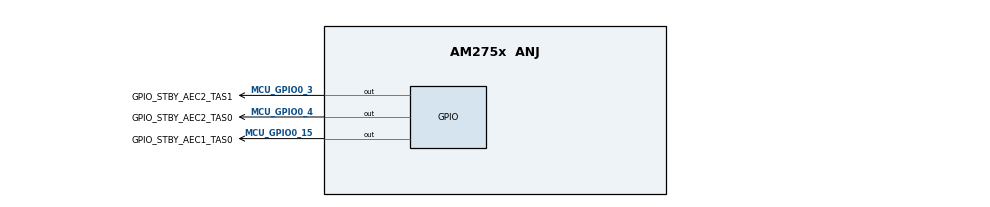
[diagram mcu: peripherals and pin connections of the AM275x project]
/**
 * @cliArgs --device "AM275x" --part "AM2754" --package "ANJ" --context "c75ss0-0" --product "MCU_PLUS_SDK@07.03.01"
 * @versions {"tool":"1.24.0+4150"}
 */

/**
 * Import the modules used in this configuration.
 */
const gpio        = scripting.addModule("/drivers/gpio/gpio", {}, false);
const gpio1       = gpio.addInstance();
const gpio2       = gpio.addInstance();
const gpio3       = gpio.addInstance();
const gpio4       = gpio.addInstance();
const i2c         = scripting.addModule("/drivers/i2c/i2c", {}, false);
const i2c1        = i2c.addInstance();
const i2c2        = i2c.addInstance();
const mcasp       = scripting.addModule("/drivers/mcasp/mcasp", {}, false);
const mcasp1      = mcasp.addInstance();
const mcasp2      = mcasp.addInstance();
const debug_log   = scripting.addModule("/kernel/dpl/debug_log");
const mmu_armv8   = scripting.addModule("/kernel/dpl/mmu_armv8", {}, false);
const mmu_armv81  = mmu_armv8.addInstance();
const mmu_armv82  = mmu_armv8.addInstance();
const mmu_armv83  = mmu_armv8.addInstance();
const mmu_armv84  = mmu_armv8.addInstance();
const mmu_armv85  = mmu_armv8.addInstance();
const mmu_armv86  = mmu_armv8.addInstance();
const mmu_armv87  = mmu_armv8.addInstance();
const mmu_armv88  = mmu_armv8.addInstance();
const mmu_armv89  = mmu_armv8.addInstance();
const mmu_armv810 = mmu_armv8.addInstance();
const mmu_armv811 = mmu_armv8.addInstance();
const mmu_armv812 = mmu_armv8.addInstance();

/**
 * Write custom configuration values to the imported modules.
 */
gpio1.$name                    = "GPIO_STBY_AEC1_TAS0";
gpio1.pinDir                   = "OUTPUT";
gpio1.useMcuGpioPins           = true;
gpio1.MCU_GPIO.$assign         = "MCU_GPIO0_15";
gpio1.MCU_GPIO.gpioPin.$assign = "MCU_GPIO0_15";

gpio2.$name        = "GPIO_STBY_AEC1_TAS1";
gpio2.pinDir       = "OUTPUT";
gpio2.GPIO.$assign = "OSPI0_CSn1";

gpio3.$name                    = "GPIO_STBY_AEC2_TAS0";
gpio3.pinDir                   = "OUTPUT";
gpio3.useMcuGpioPins           = true;
gpio3.MCU_GPIO.$assign         = "MCU_GPIO0_4";
gpio3.MCU_GPIO.gpioPin.$assign = "MCU_GPIO0_4";

gpio4.$name                    = "GPIO_STBY_AEC2_TAS1";
gpio4.pinDir                   = "OUTPUT";
gpio4.useMcuGpioPins           = true;
gpio4.MCU_GPIO.$assign         = "MCU_GPIO0_3";
gpio4.MCU_GPIO.gpioPin.$assign = "MCU_GPIO0_3";

i2c1.$name           = "CONFIG_I2C0";
i2c1.enableIntr      = false;
i2c1.I2C.$assign     = "I2C3";
i2c1.I2C.SCL.$assign = "UART0_CTSn";
i2c1.I2C.SDA.$assign = "UART0_RTSn";
i2c1.I2C_child.$name = "drivers_i2c_v0_i2c_v0_template0";

i2c2.$name           = "CONFIG_I2C1";
i2c2.enableIntr      = false;
i2c2.I2C.$assign     = "I2C5";
i2c2.I2C.SCL.$assign = "MCAN0_TX";
i2c2.I2C.SDA.$assign = "MCAN0_RX";
i2c2.I2C_child.$name = "drivers_i2c_v0_i2c_v0_template0_COPY";

mcasp1.$name                                   = "CONFIG_MCASP0";
mcasp1.txDataMask                              = 0xFFFFFFFF;
mcasp1.rxDataMask                              = 0xFFFFFFFF;
mcasp1.rxActiveSlotMask                        = 0x3;
mcasp1.rxCallbackFxn                           = "mcasp_loopback_rxcb";
mcasp1.enableLoopback                          = false;
mcasp1.clkSyncMode                             = "ASYNC";
mcasp1.TxMode                                  = "TDM";
mcasp1.NumTxSlots                              = 8;
mcasp1.txDataDelay                             = 0;
mcasp1.txFsWidth                               = 0;
mcasp1.txFsPolarity                            = 0;
mcasp1.txActiveSlotMask                        = 0xFF;
mcasp1.enableMcaspRx                           = false;
mcasp1.txCallbackFxn                           = "mcasp_txcb";
mcasp1.externTxLoopjob                         = true;
mcasp1.txLoopjobBufExtern                      = "unsigned int audio_sample[]";
mcasp1.txLoopjobBuf                            = "audio_sample";
mcasp1.txLoopjobBufLength                      = 1411200;
mcasp1.CLOCKING.$assignAllowConflicts          = "CLOCKING";
mcasp1.mcaspSer.create(1);
mcasp1.mcaspSer[0].$name                       = "CONFIG_MCASP_SER0";
mcasp1.mcaspSer[0].MCASP.$assignAllowConflicts = "MCASP0";
mcasp1.MCASP.$assignAllowConflicts             = "MCASP0";
scripting.suppress("Resource conflict,CLOCKING is also in use by @@@.+?@@@", mcasp1.CLOCKING, "$assign");
scripting.suppress("Resource conflict,MCASP0 is also in use by @@@.+?@@@", mcasp1.mcaspSer[0].MCASP, "$assign");
scripting.suppress("Resource conflict,MCASP0 is also in use by @@@.+?@@@", mcasp1.MCASP, "$assign");

mcasp2.$name                                   = "CONFIG_MCASP1";
mcasp2.txDataMask                              = 0xFFFFFFFF;
mcasp2.rxDataMask                              = 0xFFFFFFFF;
mcasp2.rxActiveSlotMask                        = 0x3;
mcasp2.rxCallbackFxn                           = "mcasp_loopback_rxcb";
mcasp2.enableLoopback                          = false;
mcasp2.clkSyncMode                             = "ASYNC";
mcasp2.TxMode                                  = "TDM";
mcasp2.NumTxSlots                              = 8;
mcasp2.txDataDelay                             = 0;
mcasp2.txFsWidth                               = 0;
mcasp2.txFsPolarity                            = 0;
mcasp2.txActiveSlotMask                        = 0xFF;
mcasp2.enableMcaspRx                           = false;
mcasp2.txCallbackFxn                           = "mcasp_txcb";
mcasp2.txLoopjobBufLength                      = 1411200;
mcasp2.externTxLoopjob                         = true;
mcasp2.txLoopjobBufExtern                      = "unsigned int audio_sample[]";
mcasp2.txLoopjobBuf                            = "audio_sample";
mcasp2.CLOCKING.$assignAllowConflicts          = "CLOCKING";
mcasp2.mcaspSer.create(1);
mcasp2.mcaspSer[0].$name                       = "CONFIG_MCASP_SER0_COPY";
mcasp2.mcaspSer[0].MCASP.$assignAllowConflicts = "MCASP2";
mcasp2.MCASP.$assignAllowConflicts             = "MCASP2";
scripting.suppress("Resource conflict,CLOCKING is also in use by @@@.+?@@@", mcasp2.CLOCKING, "$assign");
scripting.suppress("Resource conflict,MCASP2 is also in use by @@@.+?@@@", mcasp2.mcaspSer[0].MCASP, "$assign");
scripting.suppress("Resource conflict,MCASP2 is also in use by @@@.+?@@@", mcasp2.MCASP, "$assign");

const udma         = scripting.addModule("/drivers/udma/udma", {}, false);
const udma1        = udma.addInstance({}, false);
udma1.$name        = "CONFIG_UDMA0";
mcasp1.bcDmaDriver = udma1;
mcasp2.bcDmaDriver = udma1;

debug_log.enableUartLog            = true;
debug_log.uartLog.$name            = "CONFIG_UART0";
debug_log.uartLog.UART.$assign     = "UART2";
debug_log.uartLog.UART.TXD.$assign = "SPI1_CS1";

mmu_armv81.size  = 0x20000000;
mmu_armv81.$name = "REGISTER_REGION0";

mmu_armv82.vAddr = 0x20000000;
mmu_armv82.pAddr = 0x20000000;
mmu_armv82.size  = 0x20000000;
mmu_armv82.$name = "REGISTER_REGION1";

mmu_armv83.vAddr = 0x40000000;
mmu_armv83.pAddr = 0x40000000;
mmu_armv83.size  = 0x20000000;
mmu_armv83.$name = "REGISTER_REGION2";

mmu_armv84.vAddr = 0x60000000;
mmu_armv84.pAddr = 0x60000000;
mmu_armv84.size  = 0x10000000;
mmu_armv84.$name = "FSS0_DAT_REGION";

mmu_armv85.vAddr = 0x7C200000;
mmu_armv85.pAddr = 0x7C200000;
mmu_armv85.$name = "CLEC";
mmu_armv85.size  = 0x100000;

mmu_armv86.$name = "DRU";
mmu_armv86.vAddr = 0x7C400000;
mmu_armv86.pAddr = 0x7C400000;
mmu_armv86.size  = 0x300000;

mmu_armv87.$name       = "MCASP";
mmu_armv87.vAddr       = 0x2B10000;
mmu_armv87.pAddr       = 0x2B10000;
mmu_armv87.size        = 0x2000000;
mmu_armv87.privExecute = false;

mmu_armv88.$name     = "L2SRAM";
mmu_armv88.vAddr     = 0x7E000000;
mmu_armv88.pAddr     = 0x7E000000;
mmu_armv88.attribute = "MAIR7";
mmu_armv88.size      = 0x200000;

mmu_armv89.$name     = "L2SRAM_AUX";
mmu_armv89.vAddr     = 0x7E200000;
mmu_armv89.pAddr     = 0x7E200000;
mmu_armv89.size      = 0x40000;
mmu_armv89.attribute = "MAIR7";

mmu_armv810.$name     = "MSRAM_BANK0_TO_BANK3";
mmu_armv810.vAddr     = 0x80000000;
mmu_armv810.pAddr     = 0x80000000;
mmu_armv810.size      = 0x400000;
mmu_armv810.attribute = "MAIR7";

mmu_armv811.$name     = "MSRAM_BANK4_TO_BANK5";
mmu_armv811.size      = 0x200000;
mmu_armv811.vAddr     = 0x80400000;
mmu_armv811.pAddr     = 0x80400000;
mmu_armv811.attribute = "MAIR7";

mmu_armv812.$name     = "CCS_DEBUG_LOG_MEM";
mmu_armv812.vAddr     = 0x8027F000;
mmu_armv812.pAddr     = 0x8027F000;
mmu_armv812.size      = 0x1000;
mmu_armv812.attribute = "MAIR4";

/**
 * Pinmux solution for unlocked pins/peripherals. This ensures that minor changes to the automatic solver in a future
 * version of the tool will not impact the pinmux you originally saw.  These lines can be completely deleted in order to
 * re-solve from scratch.
 */
mcasp1.mcaspSer[0].MCASP.AXR0.$suggestSolution = "MCASP0_AXR0";
mcasp1.MCASP.AFSX.$suggestSolution             = "MCASP0_AFSX";
mcasp1.MCASP.ACLKX.$suggestSolution            = "MCASP0_ACLKX";
mcasp2.mcaspSer[0].MCASP.AXR0.$suggestSolution = "MCASP2_AXR0";
mcasp2.MCASP.AFSX.$suggestSolution             = "MCASP2_AFSX";
mcasp2.MCASP.ACLKX.$suggestSolution            = "MCASP2_ACLKX";
debug_log.uartLog.UART.RXD.$suggestSolution    = "MCASP0_AXR6";
